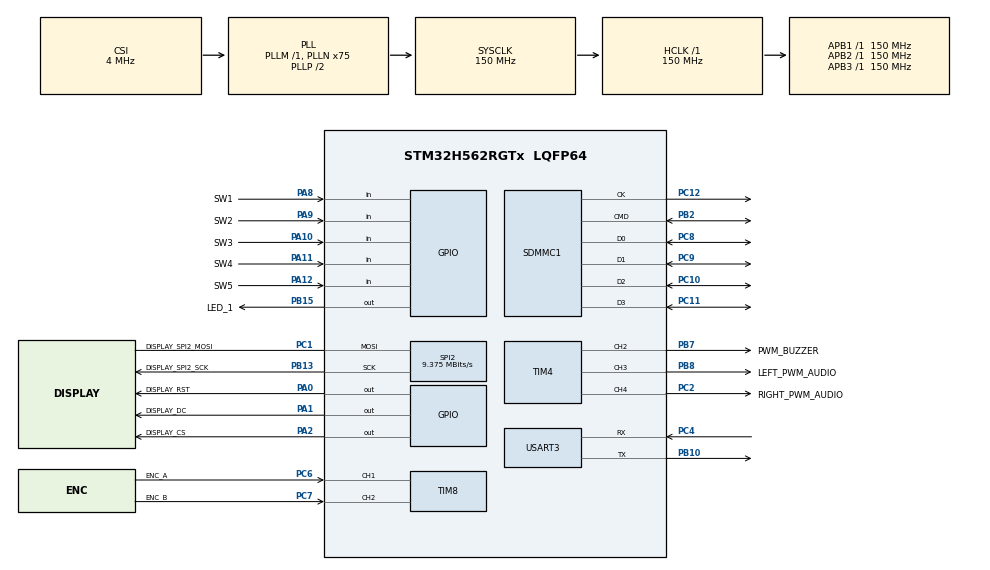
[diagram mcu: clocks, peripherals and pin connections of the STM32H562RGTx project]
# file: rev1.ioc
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BOOTPATH.BootPathName=LEGACY
BOOTPATH.UserSelectedBootPath=LEGACY
CORTEX_M33_NS.userName=CORTEX_M33
FILEX.FX_SD_INTERFACE=1
FILEX.GENERATE_FILEX_INIT_CODE=false
FILEX.useRTOS=1
Mcu.Family=STM32H5
Mcu.Name=STM32H562RGTx
Mcu.Package=LQFP64
NVIC.PriorityGroup=NVIC_PRIORITYGROUP_4
NVIC.SDMMC1_IRQn=true\:0\:0\:false\:false\:true\:false\:true\:true\:true
NVIC.TIM17_IRQn=true\:0\:0\:false\:false\:true\:false\:true\:true\:true
NVIC.TIM4_IRQn=true\:0\:0\:false\:false\:true\:false\:true\:true\:true
NVIC.TIM6_IRQn=true\:15\:0\:false\:false\:true\:false\:false\:true\:true
NVIC.TimeBase=TIM6_IRQn
NVIC.TimeBaseIP=TIM6
PA0.GPIO_Label=DISPLAY_RST
PA0.Signal=GPIO_Output
PA1.GPIO_Label=DISPLAY_DC
PA1.Signal=GPIO_Output
PA10.GPIO_Label=SW3
PA10.Signal=GPIO_Input
PA11.GPIO_Label=SW4
PA11.Signal=GPIO_Input
PA12.GPIO_Label=SW5
PA12.Signal=GPIO_Input
PA13(JTMS/SWDIO).Mode=Trace_Asynchronous_SW
PA13(JTMS/SWDIO).Signal=DEBUG_JTMS-SWDIO
PA14(JTCK/SWCLK).Mode=Trace_Asynchronous_SW
PA14(JTCK/SWCLK).Signal=DEBUG_JTCK-SWCLK
PA2.GPIO_Label=DISPLAY_CS
PA2.Signal=GPIO_Output
PA8.GPIO_Label=SW1
PA8.Signal=GPIO_Input
PA9.GPIO_Label=SW2
PA9.Signal=GPIO_Input
PB10.Mode=Asynchronous
PB10.Signal=USART3_TX
PB13.GPIO_Label=DISPLAY_SPI2_SCK
PB13.Mode=Simplex_Bidirectional_Master
PB13.Signal=SPI2_SCK
PB15.GPIO_Label=LED_1
PB15.Signal=GPIO_Output
PB2.GPIO_PuPd=GPIO_PULLUP
PB2.Mode=SD_4_bits_Wide_bus
PB2.Signal=SDMMC1_CMD
PB3(JTDO/TRACESWO).Mode=Trace_Asynchronous_SW
PB3(JTDO/TRACESWO).Signal=DEBUG_JTDO-SWO
PB7.GPIO_Label=PWM_BUZZER
PB7.Signal=S_TIM4_CH2
PB8.GPIO_Label=LEFT_PWM_AUDIO
PB8.Signal=S_TIM4_CH3
PC1.GPIO_Label=DISPLAY_SPI2_MOSI
PC1.Mode=Simplex_Bidirectional_Master
PC1.Signal=SPI2_MOSI
PC10.GPIO_PuPd=GPIO_PULLUP
PC10.Mode=SD_4_bits_Wide_bus
PC10.Signal=SDMMC1_D2
PC11.GPIO_PuPd=GPIO_PULLUP
PC11.GPIO_Speed_Default_HIGH=GPIO_SPEED_FREQ_HIGH
PC11.Mode=SD_4_bits_Wide_bus
PC11.Signal=SDMMC1_D3
PC12.Mode=SD_4_bits_Wide_bus
PC12.Signal=SDMMC1_CK
PC2.GPIO_Label=RIGHT_PWM_AUDIO
PC2.Signal=S_TIM4_CH4
PC4.Mode=Asynchronous
PC4.Signal=USART3_RX
PC6.GPIO_Label=ENC_A
PC6.Signal=S_TIM8_CH1
PC7.GPIO_Label=ENC_B
PC7.Signal=S_TIM8_CH2
PC8.GPIO_PuPd=GPIO_PULLUP
PC8.Mode=SD_4_bits_Wide_bus
PC8.Signal=SDMMC1_D0
PC9.GPIO_PuPd=GPIO_PULLUP
PC9.Mode=SD_4_bits_Wide_bus
PC9.Signal=SDMMC1_D1
ProjectManager.HeapSize=0x200
ProjectManager.StackSize=0x400
ProjectManager.TargetToolchain=CMake
RCC.ADCFreq_Value=150000000
RCC.AHBFreq_Value=150000000
RCC.APB1Freq_Value=150000000
RCC.APB1TimFreq_Value=150000000
RCC.APB2Freq_Value=150000000
RCC.APB2TimFreq_Value=150000000
RCC.APB3Freq_Value=150000000
RCC.CSI_VALUE=4000000
RCC.CortexFreq_Value=150000000
RCC.EPOD_VALUE=4000000
RCC.HCLKFreq_Value=150000000
RCC.HSE_VALUE=25000000
RCC.HSI48_VALUE=48000000
RCC.HSI_VALUE=64000000
RCC.LSE_VALUE=32768
RCC.LSIRC_VALUE=32000
RCC.PLL2FRACN=0
RCC.PLL3FRACN=0
RCC.PLLFRACN=0
RCC.PLLN=75
RCC.SYSCLKFreq_VALUE=150000000
RCC.SYSCLKSource=RCC_SYSCLKSOURCE_PLLCLK
RCC.USBFreq_Value=48000000
RCC.VCOOutputFreq_Value=300000000
SDMMC1.ClockDiv=25
SH.S_TIM4_CH2.0=TIM4_CH2,PWM Generation2 CH2
SH.S_TIM4_CH3.0=TIM4_CH3,PWM Generation3 CH3
SH.S_TIM4_CH4.0=TIM4_CH4,PWM Generation4 CH4
SH.S_TIM8_CH1.0=TIM8_CH1,Encoder_Interface
SH.S_TIM8_CH2.0=TIM8_CH2,Encoder_Interface
SPI2.BaudRatePrescaler=SPI_BAUDRATEPRESCALER_16
SPI2.CalculateBaudRate=9.375 MBits/s
SPI2.DataSize=SPI_DATASIZE_8BIT
SPI2.Direction=SPI_DIRECTION_1LINE
SPI2.Mode=SPI_MODE_MASTER
SPI2.VirtualType=VM_MASTER
TIM17.Prescaler=150 - 1
TIM4.Channel-PWM\ Generation2\ CH2=TIM_CHANNEL_2
TIM4.Channel-PWM\ Generation3\ CH3=TIM_CHANNEL_3
TIM4.Channel-PWM\ Generation4\ CH4=TIM_CHANNEL_4
TIM8.EncoderMode=TIM_ENCODERMODE_TI12
TIM8.IC1Filter=15
TIM8.IC2Filter=15
USART3.VirtualMode-Asynchronous=VM_ASYNC
VP_BOOTPATH_VS_BOOTPATH.Mode=BP_Activate
VP_CORTEX_M33_NS_VS_Hclk.Mode=Hclk_Mode
VP_FILEX_VS_FileOoSystemJjFileXJjCore.Mode=FileX_Core
VP_FILEX_VS_SDOointerface.Mode=SD_interface
VP_ICACHE_VS_ICACHE.Mode=DirectMappedCache
VP_MEMORYMAP_VS_MEMORYMAP.Mode=CurAppReg
VP_PWR_VS_LPOM.Mode=PowerOptimisation
VP_PWR_VS_SECSignals.Mode=Security/Privilege
VP_SYS_VS_tim6.Mode=TIM6
VP_THREADX_VS_RTOSJjThreadXJjCoreJjDefault.Mode=Core_Default
VP_TIM17_VS_ClockSourceINT.Mode=Enable_Timer
board=custom

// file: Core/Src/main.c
/* USER CODE BEGIN Header */
/**
 ******************************************************************************
 * @file           : main.c
 * @brief          : Main program body
 ******************************************************************************
 * @attention
 *
 * Copyright (c) 2025 STMicroelectronics.
 * All rights reserved.
 *
 * This software is licensed under terms that can be found in the LICENSE file
 * in the root directory of this software component.
 * If no LICENSE file comes with this software, it is provided AS-IS.
 *
 ******************************************************************************
 */
// clang-format off
/* USER CODE END Header */
#include "app_threadx.h"
#include "main.h"

/* USER CODE BEGIN Includes */
#include "hal_callbacks.h"
#include "hal_handles.h"

/* USER CODE END Includes */

SD_HandleTypeDef hsd1;

SPI_HandleTypeDef hspi2;

TIM_HandleTypeDef htim4;
TIM_HandleTypeDef htim8;
TIM_HandleTypeDef htim17;

UART_HandleTypeDef huart3;

void SystemClock_Config(void);
static void MX_GPIO_Init(void);
static void MX_SDMMC1_SD_Init(void);
static void MX_SPI2_Init(void);
static void MX_TIM4_Init(void);
static void MX_TIM8_Init(void);
static void MX_USART3_UART_Init(void);
static void MX_ICACHE_Init(void);
static void MX_TIM17_Init(void);

int main(void)
{

  /* MCU Configuration--------------------------------------------------------*/

  /* Reset of all peripherals, Initializes the Flash interface and the Systick. */
  HAL_Init();

  /* Configure the system clock */
  SystemClock_Config();

  /* Initialize all configured peripherals */
  MX_GPIO_Init();
  MX_SDMMC1_SD_Init();
  MX_SPI2_Init();
  MX_TIM4_Init();
  MX_TIM8_Init();
  MX_USART3_UART_Init();
  MX_ICACHE_Init();
  MX_TIM17_Init();

  MX_ThreadX_Init();

  /* We should never get here as control is now taken by the scheduler */

  /* Infinite loop */
  while (1)
  {

  }
}

void SystemClock_Config(void)
{
  RCC_OscInitTypeDef RCC_OscInitStruct = {0};
  RCC_ClkInitTypeDef RCC_ClkInitStruct = {0};

  /** Configure the main internal regulator output voltage
  */
  __HAL_PWR_VOLTAGESCALING_CONFIG(PWR_REGULATOR_VOLTAGE_SCALE2);

  while(!__HAL_PWR_GET_FLAG(PWR_FLAG_VOSRDY)) {}

  /** Initializes the RCC Oscillators according to the specified parameters
  * in the RCC_OscInitTypeDef structure.
  */
  RCC_OscInitStruct.OscillatorType = RCC_OSCILLATORTYPE_CSI;
  RCC_OscInitStruct.CSIState = RCC_CSI_ON;
  RCC_OscInitStruct.CSICalibrationValue = RCC_CSICALIBRATION_DEFAULT;
  RCC_OscInitStruct.PLL.PLLState = RCC_PLL_ON;
  RCC_OscInitStruct.PLL.PLLSource = RCC_PLL1_SOURCE_CSI;
  RCC_OscInitStruct.PLL.PLLM = 1;
  RCC_OscInitStruct.PLL.PLLN = 75;
  RCC_OscInitStruct.PLL.PLLP = 2;
  RCC_OscInitStruct.PLL.PLLQ = 2;
  RCC_OscInitStruct.PLL.PLLR = 2;
  RCC_OscInitStruct.PLL.PLLRGE = RCC_PLL1_VCIRANGE_2;
  RCC_OscInitStruct.PLL.PLLVCOSEL = RCC_PLL1_VCORANGE_WIDE;
  RCC_OscInitStruct.PLL.PLLFRACN = 0;
  if (HAL_RCC_OscConfig(&RCC_OscInitStruct) != HAL_OK)
  {
    Error_Handler();
  }

  /** Initializes the CPU, AHB and APB buses clocks
  */
  RCC_ClkInitStruct.ClockType = RCC_CLOCKTYPE_HCLK|RCC_CLOCKTYPE_SYSCLK
                              |RCC_CLOCKTYPE_PCLK1|RCC_CLOCKTYPE_PCLK2
                              |RCC_CLOCKTYPE_PCLK3;
  RCC_ClkInitStruct.SYSCLKSource = RCC_SYSCLKSOURCE_PLLCLK;
  RCC_ClkInitStruct.AHBCLKDivider = RCC_SYSCLK_DIV1;
  RCC_ClkInitStruct.APB1CLKDivider = RCC_HCLK_DIV1;
  RCC_ClkInitStruct.APB2CLKDivider = RCC_HCLK_DIV1;
  RCC_ClkInitStruct.APB3CLKDivider = RCC_HCLK_DIV1;

  if (HAL_RCC_ClockConfig(&RCC_ClkInitStruct, FLASH_LATENCY_4) != HAL_OK)
  {
    Error_Handler();
  }

  /** Configure the programming delay
  */
  __HAL_FLASH_SET_PROGRAM_DELAY(FLASH_PROGRAMMING_DELAY_2);
}

static void MX_ICACHE_Init(void)
{

  /** Enable instruction cache in 1-way (direct mapped cache)
  */
  if (HAL_ICACHE_ConfigAssociativityMode(ICACHE_1WAY) != HAL_OK)
  {
    Error_Handler();
  }
  if (HAL_ICACHE_Enable() != HAL_OK)
  {
    Error_Handler();
  }

}

static void MX_SDMMC1_SD_Init(void)
{

  hsd1.Instance = SDMMC1;
  hsd1.Init.ClockEdge = SDMMC_CLOCK_EDGE_RISING;
  hsd1.Init.ClockPowerSave = SDMMC_CLOCK_POWER_SAVE_DISABLE;
  hsd1.Init.BusWide = SDMMC_BUS_WIDE_4B;
  hsd1.Init.HardwareFlowControl = SDMMC_HARDWARE_FLOW_CONTROL_DISABLE;
  hsd1.Init.ClockDiv = 25;
  if (HAL_SD_Init(&hsd1) != HAL_OK)
  {
    Error_Handler();
  }

}

static void MX_SPI2_Init(void)
{

  /* SPI2 parameter configuration*/
  hspi2.Instance = SPI2;
  hspi2.Init.Mode = SPI_MODE_MASTER;
  hspi2.Init.Direction = SPI_DIRECTION_1LINE;
  hspi2.Init.DataSize = SPI_DATASIZE_8BIT;
  hspi2.Init.CLKPolarity = SPI_POLARITY_LOW;
  hspi2.Init.CLKPhase = SPI_PHASE_1EDGE;
  hspi2.Init.NSS = SPI_NSS_SOFT;
  hspi2.Init.BaudRatePrescaler = SPI_BAUDRATEPRESCALER_16;
  hspi2.Init.FirstBit = SPI_FIRSTBIT_MSB;
  hspi2.Init.TIMode = SPI_TIMODE_DISABLE;
  hspi2.Init.CRCCalculation = SPI_CRCCALCULATION_DISABLE;
  hspi2.Init.CRCPolynomial = 0x7;
  hspi2.Init.NSSPMode = SPI_NSS_PULSE_ENABLE;
  hspi2.Init.NSSPolarity = SPI_NSS_POLARITY_LOW;
  hspi2.Init.FifoThreshold = SPI_FIFO_THRESHOLD_01DATA;
  hspi2.Init.MasterSSIdleness = SPI_MASTER_SS_IDLENESS_00CYCLE;
  hspi2.Init.MasterInterDataIdleness = SPI_MASTER_INTERDATA_IDLENESS_00CYCLE;
  hspi2.Init.MasterReceiverAutoSusp = SPI_MASTER_RX_AUTOSUSP_DISABLE;
  hspi2.Init.MasterKeepIOState = SPI_MASTER_KEEP_IO_STATE_DISABLE;
  hspi2.Init.IOSwap = SPI_IO_SWAP_DISABLE;
  hspi2.Init.ReadyMasterManagement = SPI_RDY_MASTER_MANAGEMENT_INTERNALLY;
  hspi2.Init.ReadyPolarity = SPI_RDY_POLARITY_HIGH;
  if (HAL_SPI_Init(&hspi2) != HAL_OK)
  {
    Error_Handler();
  }

}

static void MX_TIM4_Init(void)
{

  TIM_MasterConfigTypeDef sMasterConfig = {0};
  TIM_OC_InitTypeDef sConfigOC = {0};

  htim4.Instance = TIM4;
  htim4.Init.Prescaler = 0;
  htim4.Init.CounterMode = TIM_COUNTERMODE_UP;
  htim4.Init.Period = 65535;
  htim4.Init.ClockDivision = TIM_CLOCKDIVISION_DIV1;
  htim4.Init.AutoReloadPreload = TIM_AUTORELOAD_PRELOAD_DISABLE;
  if (HAL_TIM_PWM_Init(&htim4) != HAL_OK)
  {
    Error_Handler();
  }
  sMasterConfig.MasterOutputTrigger = TIM_TRGO_RESET;
  sMasterConfig.MasterSlaveMode = TIM_MASTERSLAVEMODE_DISABLE;
  if (HAL_TIMEx_MasterConfigSynchronization(&htim4, &sMasterConfig) != HAL_OK)
  {
    Error_Handler();
  }
  sConfigOC.OCMode = TIM_OCMODE_PWM1;
  sConfigOC.Pulse = 0;
  sConfigOC.OCPolarity = TIM_OCPOLARITY_HIGH;
  sConfigOC.OCFastMode = TIM_OCFAST_DISABLE;
  if (HAL_TIM_PWM_ConfigChannel(&htim4, &sConfigOC, TIM_CHANNEL_2) != HAL_OK)
  {
    Error_Handler();
  }
  if (HAL_TIM_PWM_ConfigChannel(&htim4, &sConfigOC, TIM_CHANNEL_3) != HAL_OK)
  {
    Error_Handler();
  }
  if (HAL_TIM_PWM_ConfigChannel(&htim4, &sConfigOC, TIM_CHANNEL_4) != HAL_OK)
  {
    Error_Handler();
  }
  HAL_TIM_MspPostInit(&htim4);

}

static void MX_TIM8_Init(void)
{

  TIM_Encoder_InitTypeDef sConfig = {0};
  TIM_MasterConfigTypeDef sMasterConfig = {0};

  htim8.Instance = TIM8;
  htim8.Init.Prescaler = 0;
  htim8.Init.CounterMode = TIM_COUNTERMODE_UP;
  htim8.Init.Period = 65535;
  htim8.Init.ClockDivision = TIM_CLOCKDIVISION_DIV1;
  htim8.Init.RepetitionCounter = 0;
  htim8.Init.AutoReloadPreload = TIM_AUTORELOAD_PRELOAD_DISABLE;
  sConfig.EncoderMode = TIM_ENCODERMODE_TI12;
  sConfig.IC1Polarity = TIM_ICPOLARITY_RISING;
  sConfig.IC1Selection = TIM_ICSELECTION_DIRECTTI;
  sConfig.IC1Prescaler = TIM_ICPSC_DIV1;
  sConfig.IC1Filter = 15;
  sConfig.IC2Polarity = TIM_ICPOLARITY_RISING;
  sConfig.IC2Selection = TIM_ICSELECTION_DIRECTTI;
  sConfig.IC2Prescaler = TIM_ICPSC_DIV1;
  sConfig.IC2Filter = 15;
  if (HAL_TIM_Encoder_Init(&htim8, &sConfig) != HAL_OK)
  {
    Error_Handler();
  }
  sMasterConfig.MasterOutputTrigger = TIM_TRGO_RESET;
  sMasterConfig.MasterOutputTrigger2 = TIM_TRGO2_RESET;
  sMasterConfig.MasterSlaveMode = TIM_MASTERSLAVEMODE_DISABLE;
  if (HAL_TIMEx_MasterConfigSynchronization(&htim8, &sMasterConfig) != HAL_OK)
  {
    Error_Handler();
  }

}

static void MX_TIM17_Init(void)
{

  htim17.Instance = TIM17;
  htim17.Init.Prescaler = 150 - 1;
  htim17.Init.CounterMode = TIM_COUNTERMODE_UP;
  htim17.Init.Period = 65535;
  htim17.Init.ClockDivision = TIM_CLOCKDIVISION_DIV1;
  htim17.Init.RepetitionCounter = 0;
  htim17.Init.AutoReloadPreload = TIM_AUTORELOAD_PRELOAD_DISABLE;
  if (HAL_TIM_Base_Init(&htim17) != HAL_OK)
  {
    Error_Handler();
  }

}

static void MX_USART3_UART_Init(void)
{

  huart3.Instance = USART3;
  huart3.Init.BaudRate = 115200;
  huart3.Init.WordLength = UART_WORDLENGTH_8B;
  huart3.Init.StopBits = UART_STOPBITS_1;
  huart3.Init.Parity = UART_PARITY_NONE;
  huart3.Init.Mode = UART_MODE_TX_RX;
  huart3.Init.HwFlowCtl = UART_HWCONTROL_NONE;
  huart3.Init.OverSampling = UART_OVERSAMPLING_16;
  huart3.Init.OneBitSampling = UART_ONE_BIT_SAMPLE_DISABLE;
  huart3.Init.ClockPrescaler = UART_PRESCALER_DIV1;
  huart3.AdvancedInit.AdvFeatureInit = UART_ADVFEATURE_NO_INIT;
  if (HAL_UART_Init(&huart3) != HAL_OK)
  {
    Error_Handler();
  }
  if (HAL_UARTEx_SetTxFifoThreshold(&huart3, UART_TXFIFO_THRESHOLD_1_8) != HAL_OK)
  {
    Error_Handler();
  }
  if (HAL_UARTEx_SetRxFifoThreshold(&huart3, UART_RXFIFO_THRESHOLD_1_8) != HAL_OK)
  {
    Error_Handler();
  }
  if (HAL_UARTEx_DisableFifoMode(&huart3) != HAL_OK)
  {
    Error_Handler();
  }

}

static void MX_GPIO_Init(void)
{
  GPIO_InitTypeDef GPIO_InitStruct = {0};

  /* GPIO Ports Clock Enable */
  __HAL_RCC_GPIOC_CLK_ENABLE();
  __HAL_RCC_GPIOA_CLK_ENABLE();
  __HAL_RCC_GPIOB_CLK_ENABLE();

  /*Configure GPIO pin Output Level */
  HAL_GPIO_WritePin(GPIOA, DISPLAY_RST_Pin|DISPLAY_DC_Pin|DISPLAY_CS_Pin, GPIO_PIN_RESET);

  /*Configure GPIO pin Output Level */
  HAL_GPIO_WritePin(LED_1_GPIO_Port, LED_1_Pin, GPIO_PIN_RESET);

  /*Configure GPIO pins : DISPLAY_RST_Pin DISPLAY_DC_Pin DISPLAY_CS_Pin */
  GPIO_InitStruct.Pin = DISPLAY_RST_Pin|DISPLAY_DC_Pin|DISPLAY_CS_Pin;
  GPIO_InitStruct.Mode = GPIO_MODE_OUTPUT_PP;
  GPIO_InitStruct.Pull = GPIO_NOPULL;
  GPIO_InitStruct.Speed = GPIO_SPEED_FREQ_LOW;
  HAL_GPIO_Init(GPIOA, &GPIO_InitStruct);

  /*Configure GPIO pin : LED_1_Pin */
  GPIO_InitStruct.Pin = LED_1_Pin;
  GPIO_InitStruct.Mode = GPIO_MODE_OUTPUT_PP;
  GPIO_InitStruct.Pull = GPIO_NOPULL;
  GPIO_InitStruct.Speed = GPIO_SPEED_FREQ_LOW;
  HAL_GPIO_Init(LED_1_GPIO_Port, &GPIO_InitStruct);

  /*Configure GPIO pins : SW1_Pin SW2_Pin SW3_Pin SW4_Pin
                           SW5_Pin */
  GPIO_InitStruct.Pin = SW1_Pin|SW2_Pin|SW3_Pin|SW4_Pin
                          |SW5_Pin;
  GPIO_InitStruct.Mode = GPIO_MODE_INPUT;
  GPIO_InitStruct.Pull = GPIO_NOPULL;
  HAL_GPIO_Init(GPIOA, &GPIO_InitStruct);

}

void HAL_TIM_PeriodElapsedCallback(TIM_HandleTypeDef *htim)
{
  if (htim->Instance == TIM6)
  {
    HAL_IncTick();
  }
  /* USER CODE BEGIN Callback 1 */
  if (htim->Instance == TIM4)
  {
    TimerAuxPwmPeriodElapsedCallback();
  }
  if (htim->Instance == TIM17)
  {
    TimerLoadAudioPeriodElapsedCallback();
  }

  /* USER CODE END Callback 1 */
}

void Error_Handler(void)
{
  __disable_irq();
  while (1)
  {
  }
}
